# STM32MP21_CA35 register map
File version: 0.4
CPU: CM33 r0p1, little endian, MPU, FPU, vendor SysTick, 8 interrupt priority bits
Registers are 32-bit, read-write, reset 0x0 unless marked. A register's access mark holds for its fields unless they carry their own. Offsets are from the block's base; [hi:lo] are bit positions; {n}, {i} and the like mark numbered series; 'fields as' and 'values as' point back to an identical list.

## SYSCFG — SYSCFG register block
Base 0x44230000
Same registers: SYSCFG_S 0x54230000
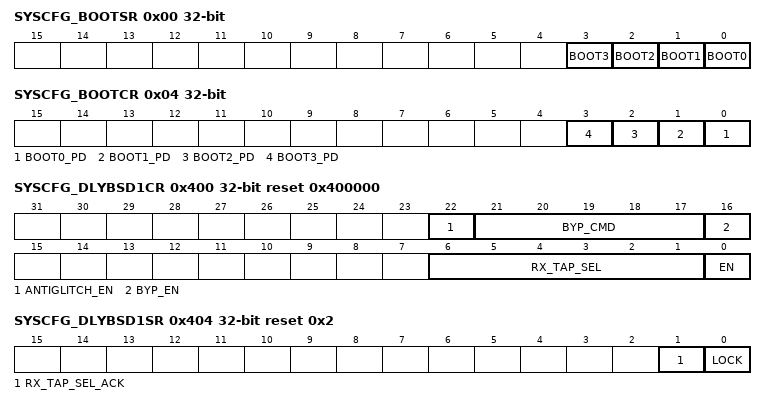
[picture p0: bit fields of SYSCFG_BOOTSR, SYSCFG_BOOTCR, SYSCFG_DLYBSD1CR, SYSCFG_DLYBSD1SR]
0x00 SYSCFG_BOOTSR ro (reset mask 0xFFFFFFF0) — SYSCFG boot pin status register
  [n] BOOT{n} (n=0..3) — BOOT{n} pin value
    0=low (BOOT{n} pin connected to VSS (or left open if BOOT{n}_PD = 0)); 1=high (BOOT{n} pin connected to VDD)
0x04 SYSCFG_BOOTCR — SYSCFG boot pin control register
  [all] fields
    0=enabled (pull-down enabled.); 1=disabled (pull-down disabled.)
  [n] BOOT{n}_PD (n=0..3) — BOOT{n} pin pull-down disable
0x400 SYSCFG_DLYBSD1CR reset 0x400000 — SYSCFG DLYBSD1 control register
  [22] ANTIGLITCH_EN
    1=The anti-glitch logic is enabled
  [21:17] BYP_CMD — Delay unit when in DLL bypass mode
    1=1 delay element enabled; 2=2 delay elements enabled; 24=all 24 delay elements enabled; 25=all 24 delay elements enabled; 31=all 24 delay elements enabled
  [16] BYP_EN — DLL bypass mode enable
    1=DLL bypass mode is enabled; 0=DLL lock mode is selected
  [6:1] RX_TAP_SEL — TAP number for RX clock selection
    0=0 tap selected; 1=1 tap is selected; 2=2 taps selected; 31=31 taps selected; 32=32 taps selected
  [0] EN — When 1, the DLL is enabled when configured in lock mode (BYP_EN = 0).
0x404 SYSCFG_DLYBSD1SR ro reset 0x2 — SYSCFG DLYBSD1 status register
  [1] RX_TAP_SEL_ACK
    1=The RX delay switched to the tap value specified in RX_TAP_SEL[5:0]
  [0] LOCK
    1=The DLL is locked
0x408 SYSCFG_SDMMC1CR — SYSCFG SDMMC1 control register
  [0] SDMMC1_VSEL — Voltage selection
    1=Change the voltage to low-voltage range (1; 0=Change the voltage to high-voltage range (3
{0xC+0x400*i} SYSCFG_SDMMC{i}ARCR (i=1..3) — SYSCFG SDMMC{i} address remapping control register
  [0] AREN — Address remapping enable
    1=Address remapping is enabled; 0=Address remapping is not enabled
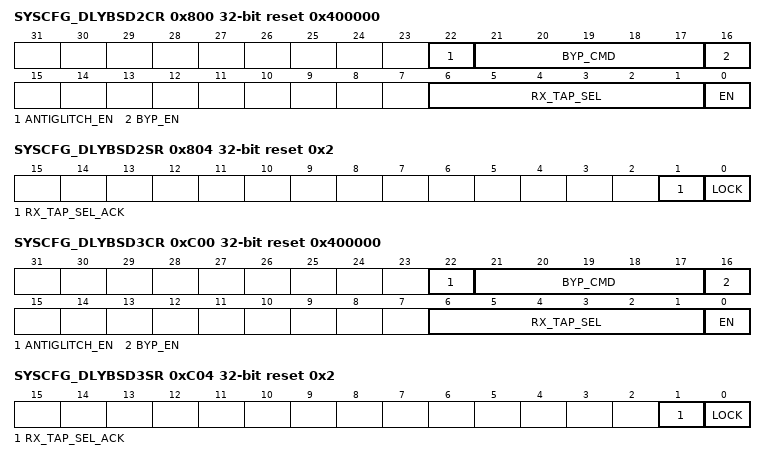
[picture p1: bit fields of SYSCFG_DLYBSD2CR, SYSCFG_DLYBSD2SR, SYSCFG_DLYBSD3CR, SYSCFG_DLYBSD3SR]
0x800 SYSCFG_DLYBSD2CR reset 0x400000 — SYSCFG DLYBSD2 control register
  [22] ANTIGLITCH_EN — Anti-glitch logic enable
    1=The anti-glitch logic is enabled
  [21:17] BYP_CMD — Delay unit when in DLL bypass mode
    values as SYSCFG_DLYBSD1CR.BYP_CMD
  [16] BYP_EN — DLL bypass mode enable
    1=DLL bypass mode is enabled; 0=DLL lock mode is selected
  [6:1] RX_TAP_SEL — TAP delay for RX clock selection
    0=0 tap selected; 1=1 tap selected; 2=2 taps selected; 31=31 taps selected; 32=32 taps selected
  [0] EN
    1=The DLL is enabled when configured in lock mode (BYP_EN = 0)
0x804 SYSCFG_DLYBSD2SR ro reset 0x2 — SYSCFG DLYBSD2 status register
  fields as SYSCFG_DLYBSD1SR
0x808 SYSCFG_SDMMC2CR — SYSCFG SDMMC2 control register
  [0] SDMMC2_VSEL — Voltage selection
    values as SYSCFG_SDMMC1CR.SDMMC1_VSEL
0xC00 SYSCFG_DLYBSD3CR reset 0x400000 — SYSCFG DLYBSD3 control register
  fields as SYSCFG_DLYBSD2CR
0xC04 SYSCFG_DLYBSD3SR ro reset 0x2 — SYSCFG DLYBSD3 status register
  [1] RX_TAP_SEL_ACK
    1=The RX delay has switched to the tap value specified in RX_TAP_SEL[5:0]
  [0] LOCK
    1=The DLL is locked
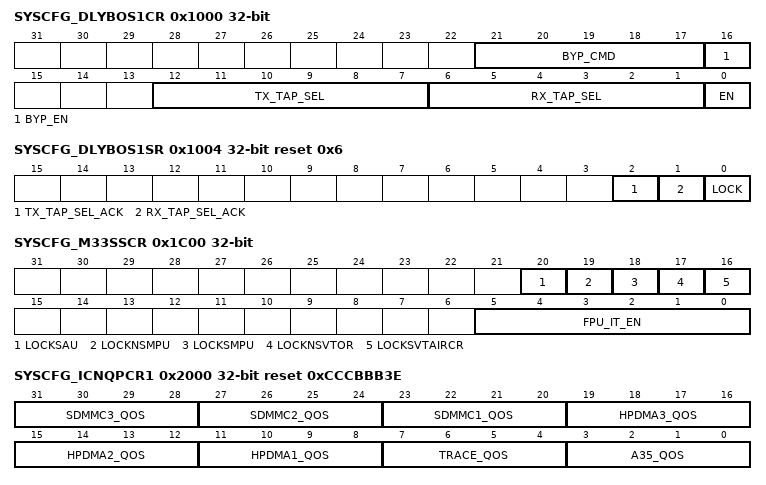
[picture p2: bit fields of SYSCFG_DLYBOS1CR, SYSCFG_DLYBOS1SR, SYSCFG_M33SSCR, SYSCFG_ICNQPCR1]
0x1000 SYSCFG_DLYBOS1CR — SYSCFG DLYBOS1 control register
  [21:17] BYP_CMD — Delay unit when in DLL bypass mode
    values as SYSCFG_DLYBSD1CR.BYP_CMD
  [16] BYP_EN — DLL bypass mode enable
    1=DLL bypass mode is enabled; 0=DLL lock mode is selected
  [12:7] TX_TAP_SEL — TAP delay for TX clock selection
    values as SYSCFG_DLYBSD2CR.RX_TAP_SEL
  [6:1] RX_TAP_SEL — TAP delay for RX clock selection
    values as SYSCFG_DLYBSD2CR.RX_TAP_SEL
  [0] EN
    values as SYSCFG_DLYBSD2CR.EN
0x1004 SYSCFG_DLYBOS1SR ro reset 0x6 — SYSCFG DLYBOS1 status register
  [2] TX_TAP_SEL_ACK
    1=The TX delay has switched to the tap value specified in TX_TAP_SEL[5:0]
  [1] RX_TAP_SEL_ACK
    values as SYSCFG_DLYBSD3SR.RX_TAP_SEL_ACK
  [0] LOCK
    1=The DLL is locked
0x1804 SYSCFG_POTTAMPRSTCR — SYSCFG potential tamper reset control register
  [0] POTTAMPRESETMASK — This bit can be set by software to mask PKA, SAES, CRYP1/2, and HASH reset in case of potential tamper.
    0=PKA, SAES, CRYP1/2, and HASH reset in case of potential tamper; 1=PKA, SAES, CRYP1/2, and HASH not reset in case of potential tamper
0x1C00 SYSCFG_M33SSCR — SYSCFG M33SS control register
  [20] LOCKSAU — Prevent changes to secure SAU memory regions already programmed.
  [19] LOCKNSMPU — Prevent changes to non-secure MPU memory regions already programmed.
  [18] LOCKSMPU — Prevent changes to programmed secure MPU memory regions.
  [17] LOCKNSVTOR — Prevent changes to non-secure vector table base address.
  [16] LOCKSVTAIRCR — Prevent changes to:
  [5:0] FPU_IT_EN — Floating point unit interrupt enable
0x2000 SYSCFG_ICNQPCR1 reset 0xCCCBBB3E — SYSCFG ICN QOS priority control register 1
  [all] fields
    0=Lowest priority; 15=Highest priority
  [31:28] SDMMC3_QOS — SDMMC3 read/write channel QoS setting
  [27:24] SDMMC2_QOS — SDMMC2 read/write channes QoS setting
  [23:20] SDMMC1_QOS — SDMMC1 read/write channel QoS setting
  [19:16] HPDMA3_QOS — HPDMA3 read/write channel QoS setting
  [15:12] HPDMA2_QOS — HPDMA2 read/write channel QoS setting
  [11:8] HPDMA1_QOS — HPDMA1 read/write channel QoS setting
  [7:4] TRACE_QOS — TRACE read/write channel QoS setting
  [3:0] A35_QOS — Cortex-A35 read/write channel QoS setting
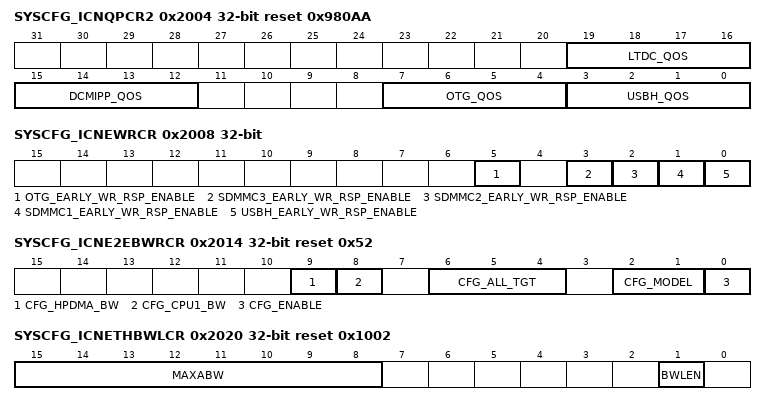
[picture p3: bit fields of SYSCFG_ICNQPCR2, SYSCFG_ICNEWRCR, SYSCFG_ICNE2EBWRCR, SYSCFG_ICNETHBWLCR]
0x2004 SYSCFG_ICNQPCR2 reset 0x980AA — SYSCFG ICN QOS priority control register 2
  [all] fields
    0=Lowest priority; 15=Highest priority
  [19:16] LTDC_QOS — LTDC read/write channels QoS setting
  [15:12] DCMIPP_QOS — DCMIPP write channel QoS setting
  [7:4] OTG_QOS — OTG read/write channel QoS setting
  [3:0] USBH_QOS — USBH(OHCI and EHCI) read/write channel QoS setting
0x2008 SYSCFG_ICNEWRCR — SYSCFG ICN early write response control register
  [all] fields
    0=Early write response disabled; 1=Early write response enabled
  [5] OTG_EARLY_WR_RSP_ENABLE — OTG early write response enable
  [3] SDMMC3_EARLY_WR_RSP_ENABLE — SDMMC3 early write response enable
  [2] SDMMC2_EARLY_WR_RSP_ENABLE — SDMMC2 early write response enable
  [1] SDMMC1_EARLY_WR_RSP_ENABLE — SDMMC1 early write response enable
  [0] USBH_EARLY_WR_RSP_ENABLE — USBH (OHCI and EHCI) early write response enable
0x2014 SYSCFG_ICNE2EBWRCR reset 0x52 — SYSCFG ICN end-to-end bandwidth regulation control register
  [9] CFG_HPDMA_BW — Triple the bandwidth (BW) allowed to HPDMA1/2/3 by the regulation.
    0=Normal bandwidth allocated to HPDMA1/2/3; 1=Increased bandwidth allocated to HPDMA1/2/3
  [8] CFG_CPU1_BW — Triple the bandwidth allowed to the CPU1 by the regulation.
    values as CFG_HPDMA_BW
  [6:4] CFG_ALL_TGT — Amount of empty CAM slots in DDR-CTRL that the regulation targets
    0=9 empty slots targeted; 1=11 empty slots targeted; 2=13 empty slots targeted; 3=15 empty slots targeted; 4=17 empty slots targeted; 5=20 empty slots targeted (default); 6=24 empty slots targeted; 7=28 empty slots targeted
  [2:1] CFG_MODEL — Defines the reactivity of the regulation feedback.
    0=Slow reaction (risk of congestion if the regulation reacts too slow); 3=Fast reaction (risk of oscillation if the regulation reacts too fast)
  [0] CFG_ENABLE — Activates the end-to-end bandwidth regulation.
    0=Regulation disabled; 1=Regulation enabled
0x2018 SYSCFG_SAFERSTCR — SYSCFG safe reset control register
  [0] CFG_ENABLE — Activates the safe reset connector.
    0=Safe reset connector disabled; 1=Safe reset connector enabled
0x2020 SYSCFG_ICNETHBWLCR reset 0x1002 — SYSCFG ICN ETH bandwidth limiter control register
  [15:8] MAXABW — Maximum allowed bandwidth
    1=Bandwidth limited at 1/128 of 2
  [1] BWLEN — Bandwidth limiter enable
    0=Bandwidth limiter disabled; 1=Bandwidth limiter enabled
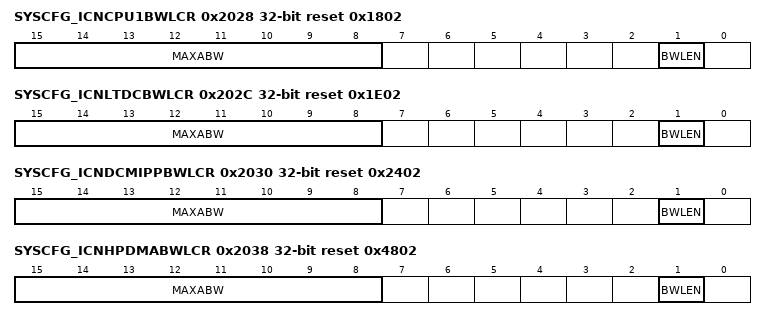
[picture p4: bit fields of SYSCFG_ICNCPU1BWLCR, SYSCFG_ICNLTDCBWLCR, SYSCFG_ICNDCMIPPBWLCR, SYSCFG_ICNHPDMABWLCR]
0x2028 SYSCFG_ICNCPU1BWLCR reset 0x1802 — SYSCFG ICN CPU1 bandwidth limiter control register
  [15:8] MAXABW — Maximum allowed bandwidth
    1=Bandwidth limited at 1/128 of 9
  [1] BWLEN — Bandwidth limiter enable
    0=Bandwidth limiter disabled; 1=Bandwidth limiter enabled
0x202C SYSCFG_ICNLTDCBWLCR reset 0x1E02 — SYSCFG ICN LTDC bandwidth limiter control register
  [15:8] MAXABW — Maximum allowed bandwidth
    1=Bandwidth limited at 1/128 of 3
  [1] BWLEN — Bandwidth limiter enable
    0=Bandwidth limiter disabled; 1=Bandwidth limiter enabled
0x2030 SYSCFG_ICNDCMIPPBWLCR reset 0x2402 — SYSCFG ICN DCMIPP bandwidth limiter control register
  fields as SYSCFG_ICNLTDCBWLCR
0x2038 SYSCFG_ICNHPDMABWLCR reset 0x4802 — SYSCFG ICN HPDMA bandwidth limiter control register
  fields as SYSCFG_ICNLTDCBWLCR
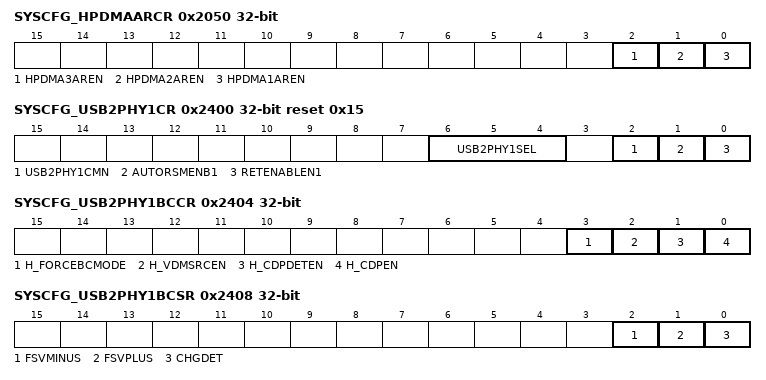
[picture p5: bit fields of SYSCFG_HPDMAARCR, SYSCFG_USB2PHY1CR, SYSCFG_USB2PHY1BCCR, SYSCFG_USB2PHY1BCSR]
0x2050 SYSCFG_HPDMAARCR — SYSCFG HPDMA address remapping control register
  [all] fields
    values as SYSCFG_SDMMC1ARCR.AREN
  [2] HPDMA3AREN — Address remapping enable
  [1] HPDMA2AREN — Address remapping enable
  [0] HPDMA1AREN — Address remapping enable
0x2400 SYSCFG_USB2PHY1CR reset 0x15 — SYSCFG USB2PHY1 control register
  [6:4] USB2PHY1SEL — PHY reference clock speed setting
    0=19; 1=20 MHz (default); 2=24 MHz
  [2] USB2PHY1CMN — Controls power down of analog blocks during Suspend and Sleep.
    0=PHY clocks are kept active during Suspend and Sleep (with the exception of PHYCLK); 1=PHY clocks are off during Suspend and Sleep
  [1] AUTORSMENB1 — Auto-resume mode enable
    0=Auto-resume disabled (default; 1=A pulse on this bit prior to enabling the retention mode, enables the auto-resume mode
  [0] RETENABLEN1 — Retention mode enable (active low)
    0=Retention mode enabled; 1=Retention mode disabled (default)
0x2404 SYSCFG_USB2PHY1BCCR — SYSCFG USB2PHY1 battery charging control register
  [3] H_FORCEBCMODE — Forces USB2PHY1 in non-driving suspend mode.
    0=Normal mode; 1=OPMODE0[1:0] is forced to non-driving, and SUSPENDM0 is forced to active
  [2] H_VDMSRCEN — Voltage source on DM for CDP port enable
    0=Voltage source disabled (default); 1=Voltage source enabled
  [1] H_CDPDETEN — Voltage detector on DP for CDP port enable
    0=voltage detector on DP disabled (default); 1=voltage detector on DP enabled
  [0] H_CDPEN — CDP behavior for Host port enable
    0=CDP behavior disabled (Host port behaves as an SDP) (default); 1=CDP behavior enabled
0x2408 SYSCFG_USB2PHY1BCSR ro — SYSCFG USB2PHY1 battery charging status register
  [2] FSVMINUS — Voltage level on DM (also output of the comparison with VLGC threshold, as defined in BC v1.
    0=VDM less than VLGC; 1=VDM > VLGC
  [1] FSVPLUS — Voltage level on DP (also output of the comparison with VLGC threshold, as defined in BC v1.
    0=VDP less than VLGC; 1=VDP > VLGC
  [0] CHGDET — Comparison of voltage on DP with VDAT_REF threshold as defined in BC v1.
    0=VDP less than VDAT_REF; 1=VDP > VDAT_REF
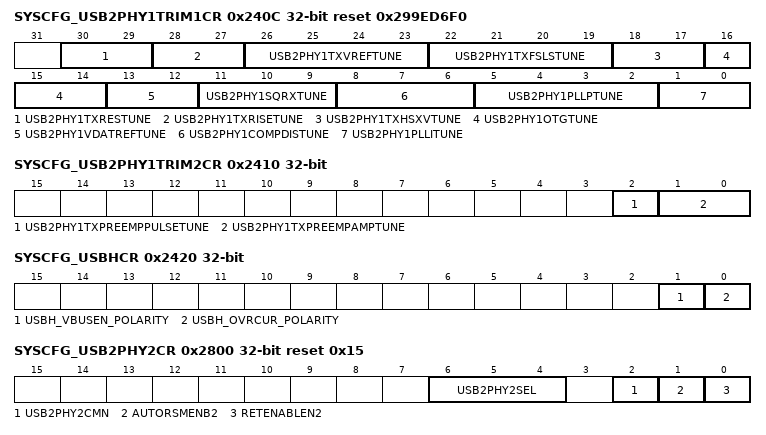
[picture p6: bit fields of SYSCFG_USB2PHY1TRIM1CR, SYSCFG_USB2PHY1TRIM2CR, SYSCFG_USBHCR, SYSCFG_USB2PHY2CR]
0x240C SYSCFG_USB2PHY1TRIM1CR reset 0x299ED6F0 — SYSCFG USB2PHY1 trimming 1 control register
  [30:29] USB2PHY1TXRESTUNE — USB source impedance adjustment
    3=Source impedance decreased by approximately 5; 2=Source impedance decreased by approximately 3; 1=Nominal; 0=Source impedance increased by approximately 1
  [28:27] USB2PHY1TXRISETUNE — High-speed transmitter rise/fall time adjustment
    3=-8; 2=-7; 1=Nominal; 0=+5
  [26:23] USB2PHY1TXVREFTUNE — HS DC voltage level adjustment
    15=+24%; 14=+22%; 13=+20%; 12=+18%; 11=+16%; 10=+14%; 9=+12%; 8=+10%; 7=+8%; 6=+6%; 5=+4%; 4=+2%; 3=Nominal; 2=-2%; 1=-4%; 0=-6%
  [22:19] USB2PHY1TXFSLSTUNE — Full-speed (FS)/low-speed (LS) source impedance adjustment
    15=-10; 7=-5; 3=Nominal; 1=+6; 0=+14%
  [18:17] USB2PHY1TXHSXVTUNE — Transmitter high-speed crossover adjustment
    3=Nominal; 2=+15mV; 1=-15mV
  [16:14] USB2PHY1OTGTUNE — Vless thansub>BUSless than/sub> valid threshold adjustment
    7=+12%; 6=+9%; 5=+6%; 4=+3%; 3=Nominal; 2=-3%; 1=-6%; 0=-9%
  [13:12] USB2PHY1VDATREFTUNE — Data detect voltage adjustment
    3=-20%; 2=-10%; 1=Nominal; 0=+10%
  [11:9] USB2PHY1SQRXTUNE — Squelch threshold adjustment
    7=-20%; 6=-15%; 5=-10%; 4=-5%; 3=Nominal; 2=+5%; 1=+10%; 0=+15%
  [8:6] USB2PHY1COMPDISTUNE — Disconnect threshold adjustment
    7=+12%; 6=+10%; 5=+7%; 4=+3%; 3=Nominal; 2=-4%; 1=-6%; 0=-9%
  [5:2] USB2PHY1PLLPTUNE — PLL proportional path tune
    15=5; 14=5x; 13=4; 12=4x; 11=4; 10=4x; 9=3; 8=3x; 7=3; 6=3x; 5=2; 4=2x; 3=2; 2=2x; 1=1; 0=1x
  [1:0] USB2PHY1PLLITUNE — PLL integral path tune
    3=2; 2=1; 1=1; 0=0
0x2410 SYSCFG_USB2PHY1TRIM2CR — SYSCFG USB2PHY1 trimming 2 control register
  [2] USB2PHY1TXPREEMPPULSETUNE — HS transmitter preemphasis duration control
    1=1x, short pre-emphasis current duration; 0=2x, long pre-emphasis current duration
  [1:0] USB2PHY1TXPREEMPAMPTUNE — HS transmitter preemphasis current control
    3=HS transmitter preemphasis circuit sources 3x preemphasis current; 2=HS transmitter preemphasis circuit sources 2x preemphasis current; 1=HS transmitter preemphasis circuit sources 1x preemphasis current; 0=HS transmitter preemphasis disabled
0x2420 SYSCFG_USBHCR — SYSCFG USBH control register
  [1] USBH_VBUSEN_POLARITY — Polarity of USBH_VBUSEN alternate function
    0=USBH_VBUSEN active high (a 1 logic level means VBUS must be enabled) (default); 1=USBH_VBUSEN active low (a 0 logic level means VBUS must be enabled)
  [0] USBH_OVRCUR_POLARITY — Polarity of USBH_OVRCUR alternate function
    0=USBH_OVRCUR active high (a 1 logic level means there is an over-current situation) (default); 1=USBH_OVRCUR active low (a 0 logic level means there is an over-current situation)
0x2424 SYSCFG_USBHARCR — SYSCFG USBH address remapping control register
  fields as SYSCFG_SDMMC1ARCR
0x2800 SYSCFG_USB2PHY2CR reset 0x15 — SYSCFG USB2PHY2 control register
  [6:4] USB2PHY2SEL — PHY reference clock speed setting
    0=19; 1=20 MHz (default); 2=24 MHz
  [2] USB2PHY2CMN — Control of power down of analog blocks during Suspend and Sleep
    values as SYSCFG_USB2PHY1CR.USB2PHY1CMN
  [1] AUTORSMENB2 — Auto-resume mode enable
    0=Auto-resume is disabled (default); 1=A pulse on this bit prior to enabling the retention mode, enables the auto-resume mode
  [0] RETENABLEN2 — Retention mode enable (active low)
    values as SYSCFG_USB2PHY1CR.RETENABLEN1
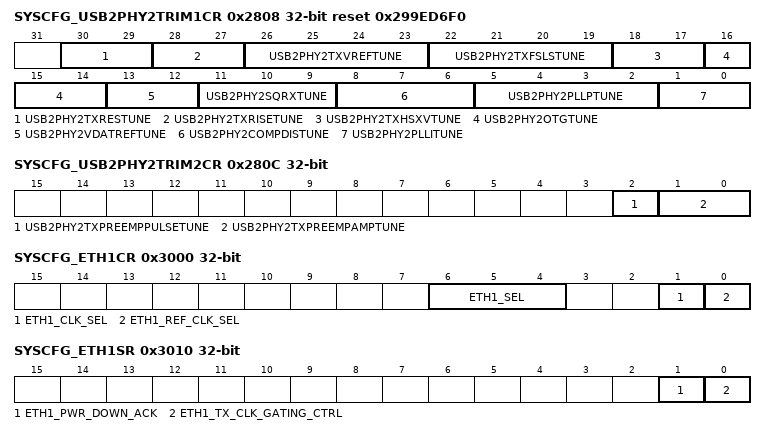
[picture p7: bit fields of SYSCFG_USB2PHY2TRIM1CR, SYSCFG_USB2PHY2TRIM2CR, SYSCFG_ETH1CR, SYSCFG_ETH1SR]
0x2808 SYSCFG_USB2PHY2TRIM1CR reset 0x299ED6F0 — SYSCFG USB2PHY2 trimming 1 control register
  [30:29] USB2PHY2TXRESTUNE — USB source impedance adjustment
    values as SYSCFG_USB2PHY1TRIM1CR.USB2PHY1TXRESTUNE
  [28:27] USB2PHY2TXRISETUNE — HS transmitter rise/fall time adjustment
    3=-8; 2=-7; 1=Nominal; 0=+5
  [26:23] USB2PHY2TXVREFTUNE — HS DC voltage level adjustment
    values as SYSCFG_USB2PHY1TRIM1CR.USB2PHY1TXVREFTUNE
  [22:19] USB2PHY2TXFSLSTUNE — Full-speed (FS)/low-speed (LS) source impedance adjustment
    15=-10; 7=-5; 3=Nominal; 1=+6; 0=+14%
  [18:17] USB2PHY2TXHSXVTUNE — Transmitter HS crossover adjustment
    3=Nominal; 2=+15mV; 1=-15mV
  [16:14] USB2PHY2OTGTUNE — VBUS valid threshold adjustment
    7=+12%; 6=+9%; 5=+6%; 4=+3%; 3=Nominal; 2=-3%; 1=-6%; 0=-9%
  [13:12] USB2PHY2VDATREFTUNE — Data detect voltage adjustment
    3=-20%; 2=-10%; 1=Nominal; 0=+10%
  [11:9] USB2PHY2SQRXTUNE — Squelch threshold adjustment
    values as SYSCFG_USB2PHY1TRIM1CR.USB2PHY1SQRXTUNE
  [8:6] USB2PHY2COMPDISTUNE — Disconnect threshold adjustment
    7=+12%; 6=+10%; 5=+7%; 4=+3%; 3=Nominal; 2=-4%; 1=-6%; 0=-9%
  [5:2] USB2PHY2PLLPTUNE — PLL proportional path tune
    values as SYSCFG_USB2PHY1TRIM1CR.USB2PHY1PLLPTUNE
  [1:0] USB2PHY2PLLITUNE — PLL integral path tune
    3=2; 2=1; 1=1; 0=0
0x280C SYSCFG_USB2PHY2TRIM2CR — SYSCFG USB2PHY2 trimming 2 control register
  [2] USB2PHY2TXPREEMPPULSETUNE — HS transmitter preemphasis duration control
    1=1x, short preemphasis current duration; 0=2x, long preemphasis current duration
  [1:0] USB2PHY2TXPREEMPAMPTUNE — HS transmitter preemphasis current control
    3=HS transmitter preemphasis circuit sources 3x preemphasis current; 2=HS transmitter preemphasis circuit sources 2x preemphasis current; 1=HS transmitter preemphasis circuit sources 1x preemphasis current; 0=HS transmitter preemphasis is disabled
0x2824 SYSCFG_OTGARCR — SYSCFG OTG address remapping control register
  fields as SYSCFG_SDMMC1ARCR
0x3000 SYSCFG_ETH1CR — SYSCFG Ethernet1 control register
  [6:4] ETH1_SEL — Ethernet 1 PHY interface selection
    0=MII; 1=RGMII; 4=RMII
  [1] ETH1_CLK_SEL — RGMII 125 MHz clock selection
    0=External clock (ETH1_CLK125) is used; 1=Internal clock from the RCC is used
  [0] ETH1_REF_CLK_SEL — Ethernet reference/RX clock selection
    0=External clock is used; 1=Internal clock from the RCC is used
0x3010 SYSCFG_ETH1SR ro — SYSCFG Ethernet1 status register
  [1] ETH1_PWR_DOWN_ACK — Asserted when the power-down sequence start has been acknowledged
  [0] ETH1_TX_CLK_GATING_CTRL — Asserted when the MAC has entered Tx LPI mode
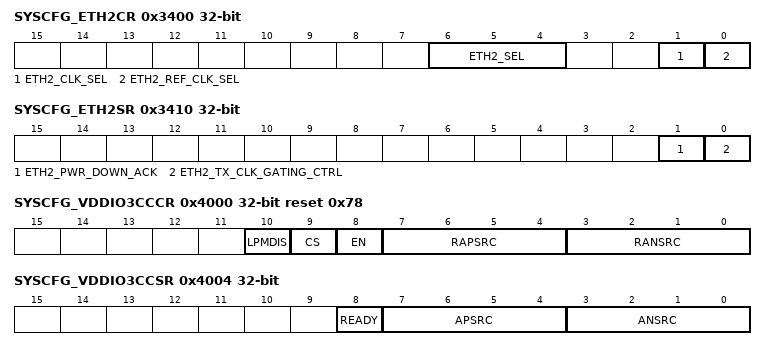
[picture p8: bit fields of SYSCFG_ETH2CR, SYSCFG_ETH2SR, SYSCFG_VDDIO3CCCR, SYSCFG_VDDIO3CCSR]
0x3400 SYSCFG_ETH2CR — SYSCFG Ethernet2 configuration register
  [6:4] ETH2_SEL — Ethernet 2 PHY interface selection
    0=MII; 1=RGMII; 4=RMII
  [1] ETH2_CLK_SEL — RGMII 125MHz clock selection
    0=External clock (ETH2_CLK125) is used; 1=Internal clock from the RCC is used
  [0] ETH2_REF_CLK_SEL — Reference/RX clock selection
    values as SYSCFG_ETH1CR.ETH1_REF_CLK_SEL
0x3410 SYSCFG_ETH2SR ro — SYSCFG Ethernet2 status register
  [1] ETH2_PWR_DOWN_ACK — Asserted when the power-down sequence start has been acknowledged
  [0] ETH2_TX_CLK_GATING_CTRL — Asserted when the MAC has entered Tx LPI mode
0x4000 SYSCFG_VDDIO3CCCR reset 0x78 — SYSCFG VDDIO3 compensation cell control register
  [10] LPMDIS — Vless thansub>DDIO3less than/sub> I/Os Compensation cell low power mode disable.
    0=IO compensation is disabled by hardware when the system enters Stop, LP-Stop and LPLV-stop modes; 1=IO compensation is not disabled by hardware when the system enters Stop, LP-Stop and LPLV-stop modes
  [9] CS — I/Os supplied by Vless thansub>DDIO3less than/sub> code selection
    0=Vless thansub>DDIO3less than/sub> I/O code from the cell (available in SYSCFG_VDDIO3CCSR); 1=Vless thansub>DDIO3less than/sub> I/O code from RANSRC[3:0] and RAPSRC[3:0] register values
  [8] EN — I/Os supplied by Vless thansub>DDIO3less than/sub> compensation cell enable
    0=Vless thansub>DDIO3less than/sub> I/Os compensation cell disabled; 1=Vless thansub>DDIO3less than/sub> I/Os compensation cell enabled
  [7:4] RAPSRC — PMOS compensation code of the I/Os supplied by Vless thansub>DDIO3less than/sub>
  [3:0] RANSRC — NMOS compensation code of the I/Os supplied by Vless thansub>DDIO3less than/sub>
0x4004 SYSCFG_VDDIO3CCSR ro — SYSCFG VDDIO3 compensation cell status register
  [8] READY — Vless thansub>DDIO3 less than/sub>I/O compensation cell ready flag
    0=Vless thansub>DDIO3 less than/sub>I/O compensation cell not ready; 1=Vless thansub>DDIO3 less than/sub>I/O compensation cell ready
  [7:4] APSRC — PMOS compensation value of the I/Os supplied by Vless thansub>DDIO3less than/sub>
  [3:0] ANSRC — NMOS compensation value of the I/Os supplied by Vless thansub>DDIO3less than/sub>
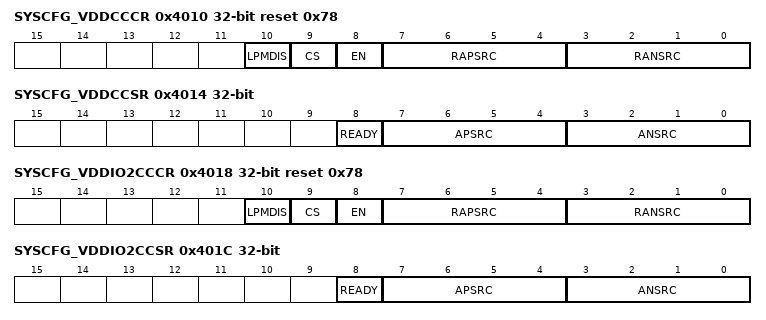
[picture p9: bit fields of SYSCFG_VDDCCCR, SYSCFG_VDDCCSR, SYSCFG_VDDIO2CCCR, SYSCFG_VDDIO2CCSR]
0x4010 SYSCFG_VDDCCCR reset 0x78 — SYSCFG VDD compensation cell control register
  [10] LPMDIS — Vless thansub>DDless than/sub> I/Os Compensation cell low power mode disable.
    values as SYSCFG_VDDIO3CCCR.LPMDIS
  [9] CS — Vless thansub>DDless than/sub> I/O code selection
    0=Vless thansub>DDless than/sub> I/O code from the cell (available in SYSCFG_VDDCCSR); 1=Vless thansub>DDless than/sub> I/O code from RANSRC[3:0] and RAPSRC[3:0] values
  [8] EN — Vless thansub>DDless than/sub> I/O compensation cell enable
    0=Vless thansub>DDless than/sub> I/Os compensation cell disabled; 1=Vless thansub>DDless than/sub> I/Os compensation cell enabled
  [7:4] RAPSRC — PMOS compensation code of the I/Os supplied by Vless thansub>DDless than/sub>
  [3:0] RANSRC — NMOS compensation code of the I/Os supplied by Vless thansub>DDless than/sub>
0x4014 SYSCFG_VDDCCSR ro — SYSCFG VDD compensation cell status register
  [8] READY — Vless thansub>DD less than/sub>I/O compensation cell ready flag
    0=Vless thansub>DD less than/sub>I/O compensation cell not ready; 1=Vless thansub>DD less than/sub>I/O compensation cell ready
  [7:4] APSRC — PMOS compensation value of the I/Os supplied by Vless thansub>DDless than/sub>
  [3:0] ANSRC — NMOS compensation value of the I/Os supplied by Vless thansub>DDless than/sub>
0x4018 SYSCFG_VDDIO2CCCR reset 0x78 — SYSCFG VDDIO2 compensation cell control register
  [10] LPMDIS — Vless thansub>DDIO2less than/sub> I/Os Compensation cell low power mode disable.
    values as SYSCFG_VDDIO3CCCR.LPMDIS
  [9] CS — Vless thansub>DDIO2less than/sub> I/O code selection
    0=Vless thansub>DDIO2less than/sub> I/O code from the cell (available in the SYSCFG_VDDIO2CCSR); 1=Vless thansub>DDIO2less than/sub> I/O code from RANSRC[3:0] and RAPSRC[3:0] register values
  [8] EN — Vless thansub>DDIO2less than/sub> I/O compensation cell enable
    0=Vless thansub>DDIO2less than/sub> I/O compensation cell disabled; 1=Vless thansub>DDIO2less than/sub> I/O compensation cell enabled
  [7:4] RAPSRC — PMOS compensation code of the I/Os supplied by Vless thansub>DDIO2less than/sub>
  [3:0] RANSRC — NMOS compensation code of the I/Os supplied by Vless thansub>DDIO2less than/sub>
0x401C SYSCFG_VDDIO2CCSR ro — SYSCFG VDDIO2 compensation cell status register
  [8] READY — Vless thansub>DDIO2 less than/sub>I/O compensation cell ready flag
    0=Vless thansub>DDIO2 less than/sub>I/O compensation cell not ready; 1=Vless thansub>DDIO2 less than/sub>I/O compensation cell ready
  [7:4] APSRC — PMOS compensation value of the I/Os supplied by Vless thansub>DDIO2less than/sub>
  [3:0] ANSRC — NMOS compensation value of the I/Os supplied by Vless thansub>DDIO2less than/sub>
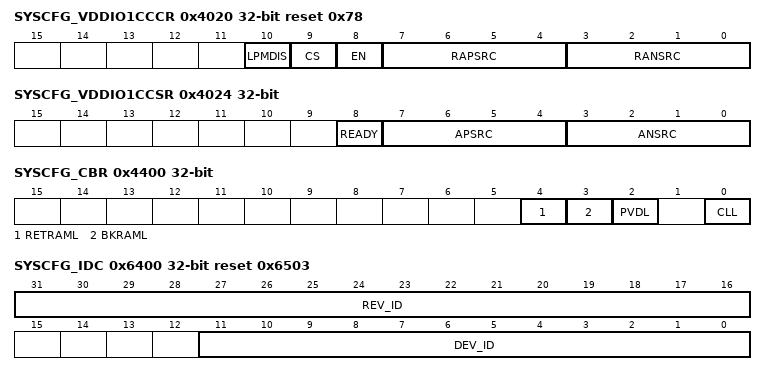
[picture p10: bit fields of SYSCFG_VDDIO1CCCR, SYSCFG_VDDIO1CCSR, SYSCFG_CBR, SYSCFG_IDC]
0x4020 SYSCFG_VDDIO1CCCR reset 0x78 — SYSCFG VDDIO1 compensation cell control register
  [10] LPMDIS — Vless thansub>DDIO1less than/sub> I/Os Compensation cell low power mode disable.
    values as SYSCFG_VDDIO3CCCR.LPMDIS
  [9] CS — Vless thansub>DDIO1less than/sub> I/O code selection
    0=Vless thansub>DDIO1less than/sub> I/O code from the cell (available in SYSCFG_VDDIO1CCSR); 1=Vless thansub>DDIO1less than/sub> I/O code from RANSRC[3:0] and RAPSRC[3:0] values
  [8] EN — Vless thansub>DDIO1less than/sub> I/O compensation cell enable
    0=Vless thansub>DDIO1less than/sub> I/O compensation cell disabled; 1=Vless thansub>DDIO1less than/sub> I/O compensation cell enabled
  [7:4] RAPSRC — PMOS compensation code of the I/Os supplied by Vless thansub>DDIO1less than/sub>
  [3:0] RANSRC — NMOS compensation code of the I/Os supplied by Vless thansub>DDIO1less than/sub>
0x4024 SYSCFG_VDDIO1CCSR ro — SYSCFG VDDIO1 compensation cell status register
  [8] READY — Vless thansub>DDIO1 less than/sub>I/O compensation cell ready flag
    0=Vless thansub>DDIO1 less than/sub>I/O compensation cell not ready; 1=Vless thansub>DDIO1 less than/sub>I/O compensation cell ready
  [7:4] APSRC — PMOS compensation value of the I/Os supplied by Vless thansub>DDIO1less than/sub>
  [3:0] ANSRC — NMOS compensation value of the I/Os supplied by Vless thansub>DDIO1less than/sub>
0x4400 SYSCFG_CBR rw-once — SYSCFG control timer break register
  [4] RETRAML — RETRAM double ECC error lock
    0=RETRAM double ECC error signal disconnected from TIM1/8/15/16/17/20 break inputs; 1=RETRAM double ECC error signal connected to TIM1/8/15/16/17/20 break inputs
  [3] BKRAML — BKPSRAM double ECC error lock
    0=BKPSRAM double ECC error signal disconnected from TIM1/8/15/16/17/20 break inputs; 1=BKPSRAM double ECC error signal connected to TIM1/8/15/16/17/20 break inputs
  [2] PVDL — PVD lock enable
    0=PVD interrupt disconnected from TIM1/8/15/16/17 break input; 1=PVD interrupt connected to TIM1/8/15/16/17 break input
  [0] CLL — Cortex-M33 LOCKUP (HardFault) output enable
    0=Cortex-M33 LOCKUP output disconnected from TIM1/8/15/16/17 break inputs; 1=Cortex-M33 LOCKUP output connected to TIM1/8/15/16/17 break inputs
0x5400 SYSCFG_HDPUSBDBGCR — SYSCFG HDP USB debug control register
  [0] SELUSBDBG — Selects debug signals to be routed to the Hardware Debug Port
    0=debug signals from the USB Host High Speed port are routed to the HDP; 1=debug signals from the USB OTG High Speed port are routed to the HDP
0x6400 SYSCFG_IDC ro reset 0x6503 (reset mask 0xFFFF) — SYSCFG device ID register
  [31:16] REV_ID — Device revision
  [11:0] DEV_ID — Device ID
    0x503=STM32MP21xx
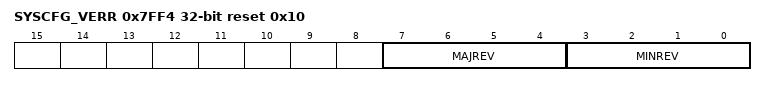
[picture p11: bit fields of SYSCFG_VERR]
0x7FF4 SYSCFG_VERR ro reset 0x10 — SYSCFG version register
  [7:4] MAJREV — SYSCFG major revision
  [3:0] MINREV — SYSCFG minor revision
0x7FF8 SYSCFG_IPIDR ro reset 0x30001 — SYSCFG identification register
  [31:0] ID — SYSCFG identifier
0x7FFC SYSCFG_SIDR ro reset 0xA3C5DD40 — SYSCFG size identification register
  [31:0] SID — Size identification
